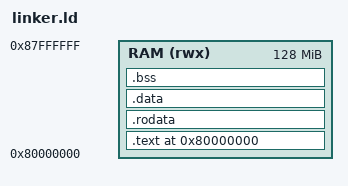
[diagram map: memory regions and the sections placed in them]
/* Linker script para RISC-V RV32I */
OUTPUT_ARCH(riscv)
ENTRY(_start)

MEMORY
{
    RAM (rwx) : ORIGIN = 0x80000000, LENGTH = 128M
}

SECTIONS
{
    . = 0x80000000;

    .text : {
        *(.text.init)
        *(.text*)
    } > RAM

    .rodata : {
        *(.rodata*)
    } > RAM

    .data : {
        *(.data*)
    } > RAM

    .bss : {
        _bss_start = .;
        *(.bss*)
        *(COMMON)
        _bss_end = .;
    } > RAM

    . = ALIGN(16);
    _stack_start = .;
    . = . + 0x10000;  /* 64KB stack */
    _stack_top = .;

    _heap_start = .;
}
